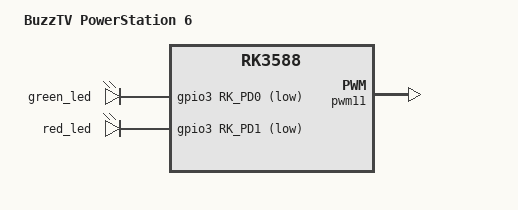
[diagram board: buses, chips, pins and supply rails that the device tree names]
// SPDX-License-Identifier: (GPL-2.0+ OR MIT)
/*
 * Copyright (c) 2021 Rockchip Electronics Co., Ltd
 *
 */

/dts-v1/;
#include "rk3588.dtsi"
#include "rk3588-u-boot.dtsi"
#include <dt-bindings/input/input.h>

/ {
	model = "BuzzTV PowerStation 6";
	compatible = "rockchip,rk3588-evb", "rockchip,rk3588";

	adc-keys {
		compatible = "adc-keys";
		io-channels = <&saradc 1>;
		io-channel-names = "buttons";
		keyup-threshold-microvolt = <1800000>;
		u-boot,dm-pre-reloc;
		status = "okay";
	};

	leds {
		compatible = "gpio-leds";
		green_led: green-led {
			gpios = <&gpio3 RK_PD0 GPIO_ACTIVE_LOW>;
			default-state = "on";
		};
		red_led: red-led {
			gpios = <&gpio3 RK_PD1 GPIO_ACTIVE_LOW>;
			default-state = "off";
		};
	};
};

&pwm11 {
	compatible = "rockchip,remotectl-pwm";
	pinctrl-names = "default";
	pinctrl-0 = <&pwm11m3_pins>;
	remote_pwm_id = <3>;
	handle_cpu_id = <1>;
	remote_support_psci = <0>;
	status = "okay";

	ir_key1 { // BuzzTV remote
		rockchip,usercode = <0xbd02>;
		rockchip,key_table =
			<0xba KEY_POWER>,
			<0x0c KEY_FIND>,
			<0x7f KEY_MUTE>,
			<0x0b KEY_FAVORITES>,
			<0xa3 69>,
			<0xaf 600>,
			<0x25 KEY_REWIND>,
			<0x9d KEY_PLAY>,
			<0x7b KEY_FASTFORWARD>,
			<0x0a KEY_RECORD>,
			<0x2b KEY_STOP>,
			<0x09 KEY_FN_F4>,
			<0x76 KEY_ZOOMOUT>,
			<0x08 KEY_FN_F12>,
			<0x07 KEY_PVR>,
			<0x29 KEY_MENU>,
			<0x2f KEY_BACK>,
			<0x35 KEY_UP>,
			<0x66 KEY_LEFT>,
			<0x31 KEY_REPLY>,
			<0x3e KEY_RIGHT>,
			<0x2d KEY_DOWN>,
			<0x27 KEY_FN_F8>,
			<0xae KEY_FN_F3>,
			<0x63 KEY_TV>,
			<0x6a KEY_HOME>,
			<0x06 KEY_EPG>,
			<0x22 KEY_VOLUMEUP>,
			<0x73 KEY_VOLUMEDOWN>,
			<0x65 KEY_CHANNELUP>,
			<0x32 KEY_CHANNELDOWN>,
			<0x6d KEY_1>,
			<0x6c KEY_2>,
			<0x33 KEY_3>,
			<0x71 KEY_4>,
			<0x70 KEY_5>,
			<0x37 KEY_6>,
			<0x75 KEY_7>,
			<0x74 KEY_8>,
			<0x3b KEY_9>,
			<0x78 KEY_0>,
			<0x26 KEY_PAGEDOWN>,
			<0x7d KEY_PAGEUP>,
			<0xb9 KEY_RED>,
			<0xb8 KEY_GREEN>,
			<0xb7 KEY_YELLOW>,
			<0xb6 KEY_BLUE>;
	};
};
